# STM32MP13xx register map
File version: 1.5
CPU: CA7 r0p0, little endian, MPU, FPU, 4 interrupt priority bits
Registers are 32-bit, read-write, reset 0x0 unless marked. A register's access mark holds for its fields unless they carry their own. Offsets are from the block's base; [hi:lo] are bit positions; {n}, {i} and the like mark numbered series.

## HASH — HASH register bank
Base 0x54003000
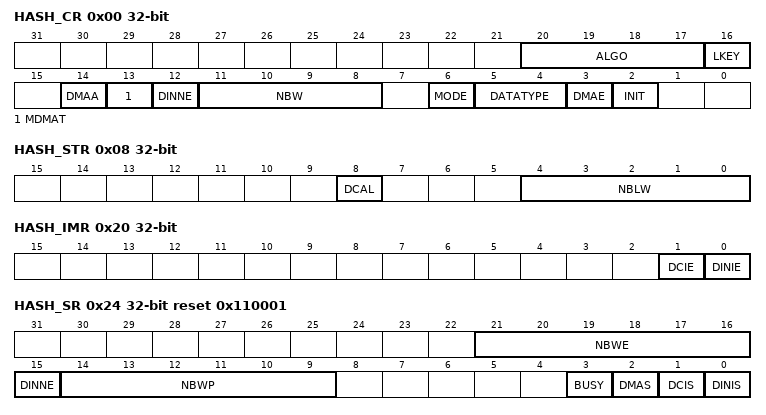
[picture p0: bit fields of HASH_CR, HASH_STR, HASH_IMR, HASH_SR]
0x00 HASH_CR access per field — HASH control register
  [20:17] ALGO rw — Algorithm selection These bits select the hash algorithm: 11xx: reserved This selection is only taken into account when the INIT bit is set. Changing this bitfield during a computation has no effect. When the ALGO bitfield is updated and INIT bit is set, NBWE in HASH_SR is automatically updated to 0x11 when ALGOÂ =Â 0x00XX.
    0=SHA-1; 2=SHA2-224; 3=SHA2-256; 12=SHA2-384; 13=SHA2-512/224; 14=SHA2-512/256; 15=SHA2-512; 4=SHA3-224; 5=SHA3-256; 6=SHA3-384; 7=SHA3-512; 8=SHAKE128; 9=SHAKE256; 10=RawSHAKE128; 11=RawSHAKE256
  [16] LKEY rw — Long key selection The application must set this bit if the HMAC key is greater than the block size corresponding to the hash algorithm (see algorithms for details). For example the block size is 64 bytes for SHA2-256. This selection is only taken into account when the INIT and MODE bits are set (HMAC mode selected). Changing this bit during a computation has no effect.
    0=HMAC key is shorter or equal to the block size (short key). The actual key value written in HASH_DIN is used during the HMAC computation.; 1=HMAC key is longer than the block size (long key). The hash of the key is used instead of the real key during the HMAC computation.
  [14] DMAA rw — DMA Abort This bit is used to abort the usage of DMA to compute a digest. When DMAA is set, DMA requests are no more issued towards the DMA, with DMAE in HASH_CR register and DMAS in HASH_SR register both cleared. If DMAA is read, DMAA always returns 0. Writing 0 to this bit has no effect.
  [13] MDMAT rw — Multiple DMA transfers This bit is set when hashing large files when multiple DMA transfers are needed.
    0=DCAL is automatically set at the end of a DMA transfer; 1=DCAL is not automatically set at the end of a DMA transfer
  [12] DINNE ro — DIN not empty Refer to DINNE bit of HASH_SR for a description of DINNE bit. This bit is read-only.
  [11:8] NBW ro — Number of words already pushed Refer to NBWP[3:0] bitfield of HASH_SR for a description of NBW[3:0] bitfield. This bit is read-only.
  [6] MODE rw — Mode selection This bit selects the normal or the keyed HMAC mode for the selected algorithm: This selection is only taken into account when the INIT bit is set. Changing this bit during a computation has no effect.
    0=Hash mode selected; 1=HMAC mode selected. LKEY bit must be set if the key being used is longer than the algorithm block size.
  [5:4] DATATYPE rw — Data type selection This bitfield defines the format of the data entered into the HASH_DIN register:
    0=32-bit data. The data written into HASH_DIN are directly used by the HASH processing, without reordering.; 1=16-bit data or half-word. The data written into HASH_DIN are considered as two half-words, and are swapped before being used by the HASH processing.; 2=8-bit data or bytes. The data written into HASH_DIN are considered as four bytes, and are swapped before being used by the HASH processing.; 3=bit data or bit string. The data written into HASH_DIN are considered as 32 bits (1st bit of the string at position 0), and are swapped before being used by the HASH processing (1st bit of the string at position 31).
  [3] DMAE rw — DMA enable After this bit is set, it is cleared by hardware while the last data of the message is written into the hash processor. Setting this bit to 0 while a DMA transfer is ongoing does not abort the current transfer. Instead, the DMA interface of the HASH remains internally enabled until the transfer is completed or INIT is written to 1. Setting INIT bit to 1 does not clear DMAE bit.
    0=DMA transfers disabled; 1=DMA transfers enabled. A DMA request is sent as soon as the hash core is ready to receive data.
  [2] INIT rw — Initialize message digest calculation Writing this bit to 1 resets the hash processor core, so that the HASH is ready to compute the message digest of a new message. Writing this bit to 0 has no effect. Reading this bit always returns 0.
0x04 HASH_DIN wo — HASH data input register
  [31:0] DATAIN — Data input Writing this register pushes the current register content into the FIFO, and the register takes the new value presented on the AHB bus. Reading this register returns zeros.
0x08 HASH_STR — HASH start register
  [8] DCAL — Digest calculation Writing this bit to 1 starts the message padding using the previously written value of NBLW, and starts the calculation of the final message digest with all the data words written to the input FIFO since the INIT bit was last written to 1. Reading this bit returns 0.
  [4:0] NBLW — Number of valid bits in the last word When the last word of the message bit string is written to HASH_DIN register, the hash processor takes only the valid bits, specified as below, after internal data swapping: ... Note: When SHA-3 is selected, bits 0 to 2 are kept at zero (byte oriented input). The above mechanism is valid only if DCALÂ =Â 0. If NBLW bits are written while DCAL is set to 1, the NBLW bitfield remains unchanged. In other words it is not possible to configure NBLW and set DCAL at the same time. Reading NBLW bits returns the last value written to NBLW.
    0=All the 32 bits of the last data written are valid message bits, that is M[31:0]; 1=Only one bit of the last data written (after swapping) is valid, that is M[0]; 2=Only two bits of the last data written (after swapping) are valid, that is M[1:0]; 3=Only three bits of the last data written (after swapping) are valid that is M[2:0]; 31=Only 31 bits of the last data written (after swapping) are valid that is M[30:0]
{0xC+4i} HASH_HRA{i} ro (i=0..4) — HASH aliased digest register {i}
  [31:0] H — Hash data Refer to introduction.
0x20 HASH_IMR
  [1] DCIE — Digest calculation completion interrupt enable
    0=Digest calculation completion interrupt disabled; 1=Digest calculation completion interrupt enabled
  [0] DINIE — Data input interrupt enable
    0=Data input interrupt disabled; 1=Data input interrupt enabled
0x24 HASH_SR access per field reset 0x110001
  [21:16] NBWE ro — Number of words expected This bitfield reflects the number of words in the message that must be pushed into the FIFO to trigger a partial computation. NBWE is decremented by 1 when a write access is performed to the HASH_DIN register. NBWE is set to the expected block size +1 in words when INIT bit is set in HASH_CR. It is set to the expected block size when the partial digest calculation ends.
  [15] DINNE ro — DIN not empty This bit is set when the HASH_DIN register holds valid data (that is after being written at least once). It is cleared when either the INIT bit (initialization) or the DCAL bit (completion of the previous message processing) is written to 1.
    0=No data are present in the data input buffer; 1=The input buffer contains at least one word of data
  [14:9] NBWP ro — Number of words already pushed This bitfield is the exact number of words in the message that have already been pushed into the FIFO. NBWP is incremented by 1 when a write access is performed to the HASH_DIN register. When a digest calculation starts, NBWP is updated to NBWP- block size (in words), and NBWP goes to zero when the INIT bit is written to 1.
  [3] BUSY ro — Busy bit
    0=No block is currently being processed; 1=The hash core is processing a block of data
  [2] DMAS ro — DMA Status This bit provides information on the DMA interface activity. It is set with DMAE and cleared when DMAEÂ =Â 0 and no DMA transfer is ongoing. No interrupt is associated with this bit.
    0=DMA interface is disabled (DMAE = 0) and no transfer is ongoing; 1=DMA interface is enabled (DMAE = 1) or a transfer is ongoing
  [1] DCIS rw — Digest calculation completion interrupt status This bit is set by hardware when a digest becomes ready (the whole message has been processed). It is cleared by writing it to 0 or by writing the INIT bit to 1 in the HASH_CR register.
    0=No digest available in the HASH_HRx registers (zeros are returned); 1=Digest calculation complete, a digest is available in the HASH_HRx registers. An interrupt is generated if the DCIE bit is set in the HASH_IMR register.
  [0] DINIS rw — Data input interrupt status This bit is set by hardware when the FIFO is ready to get a new block (16 locations are free). It is cleared by writing it to 0 or by writing the HASH_DIN register. When DINISÂ =Â 0, HASH_CSRx registers reads as zero.
    0=Less than 16 locations are free in the input buffer; 1=A new block can be entered into the input buffer. An interrupt is generated if the DINIE bit is set in the HASH_IMR register.
{0xF8+4i} HASH_CSR{i} reset 0x220002 (i=0..80) — HASH context swap register {i}
  [31:0] CS{i} — Context swap x (xÂ =Â 0 to 102) Refer to introduction.
{0xF8+4i} HASH_CSR{i} reset 0x220002 (i=81..102) — HASH context swap register {i}
  [31:0] CSx — Context swap x (xÂ =Â 0 to 102) Refer to introduction.
{0x310+4i} HASH_HR{i} ro (i=0..4)
  [31:0] Hx — Hash data x (xÂ =Â 0 to 4) Refer to introduction.
{0x310+4i} HASH_HR{i} ro (i=5..49)
  [31:0] Hx — Hash data x (xÂ =Â 5 to 49) Refer to introduction.
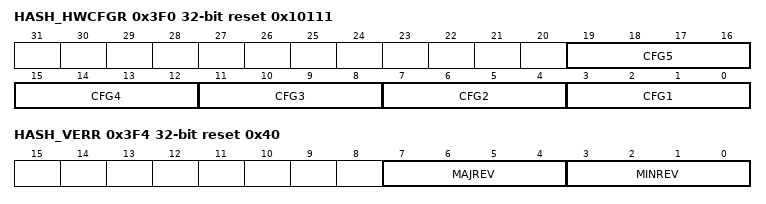
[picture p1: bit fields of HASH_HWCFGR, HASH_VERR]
0x3F0 HASH_HWCFGR ro reset 0x10111
  [19:16] CFG5 — HW generic 5 This bitfield reflects that the SHA384 and SHA512 algorithms are supported.
  [15:12] CFG4 — HW generic 4 This bitfield is read as zero.
  [11:8] CFG3 — HW generic 3 This bitfield reflects that the SHA3 algorithm is supported.
  [7:4] CFG2 — HW generic 2 This bitfield reflects that the HMAC is supported.
  [3:0] CFG1 — HW generic 1 this bitfield reflects the DMA type connected to this HASH peripheral.
0x3F4 HASH_VERR ro reset 0x40
  [7:4] MAJREV — Major revision These bits return the HASH major revision
  [3:0] MINREV — Minor revision These bits return the HASH minor revision
0x3F8 HASH_IPIDR ro reset 0x170031
  [31:0] ID — [31: 0]: Identifier These bits return the unique identifier of the HASH peripheral.
0x3FC HASH_SIDR ro reset 0xA3C5DD01
  [31:0] SID — Size identification code This bitfield returns the size identification code of the HASH peripheral as defined below: Bits[31:8] = 0xA3C5DD (fixed code) Bits[7:0] = 0x01 (1-Kbyte address decoding)
